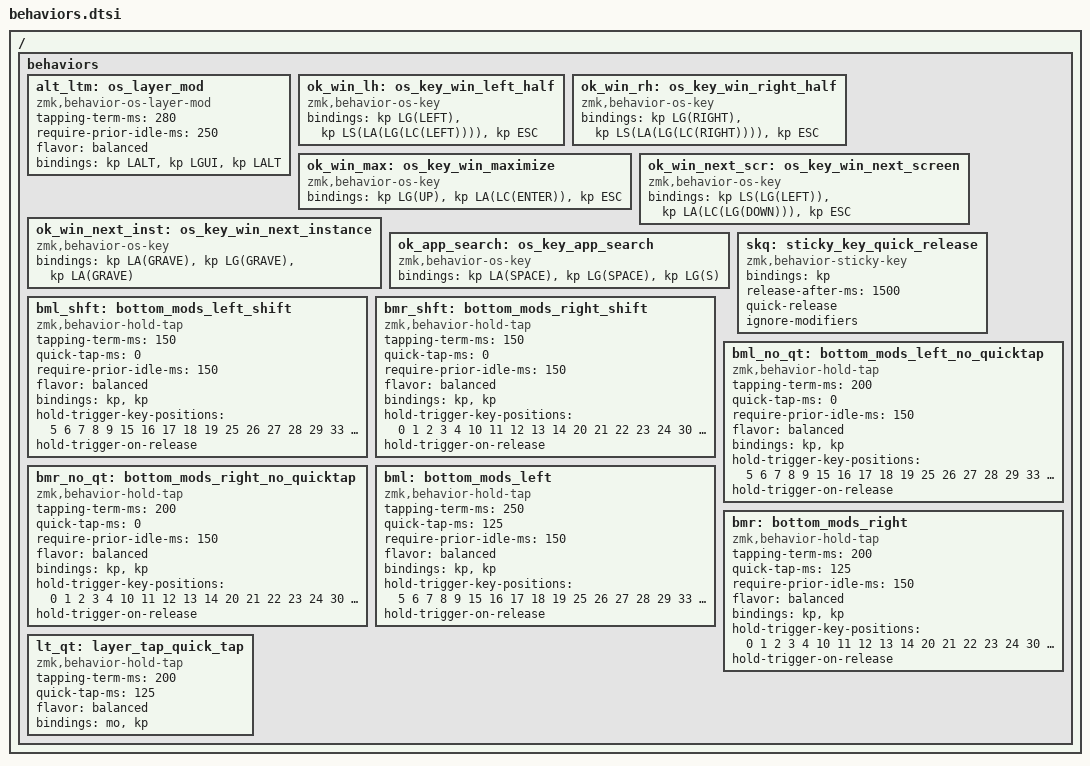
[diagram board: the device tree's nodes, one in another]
/ {
    behaviors {
        alt_ltm: os_layer_mod {
            compatible = "zmk,behavior-os-layer-mod";
            #binding-cells = <2>;
            tapping-term-ms = <280>;
            require-prior-idle-ms = <250>;
            flavor = "balanced";
            /*             Win         Mac         Lin  */
            bindings = <&kp LALT>, <&kp LGUI>, <&kp LALT>;
        };

        ok_win_lh: os_key_win_left_half {
            compatible = "zmk,behavior-os-key";
            #binding-cells = <0>;
            /*            Win           Mac           Lin  */
            bindings = <&kp LG(LEFT)>, <&kp LS(LA(LG(LC(LEFT))))>, <&kp ESC>;
        };

        ok_win_rh: os_key_win_right_half {
            compatible = "zmk,behavior-os-key";
            #binding-cells = <0>;
            /*            Win           Mac           Lin  */
            bindings = <&kp LG(RIGHT)>, <&kp LS(LA(LG(LC(RIGHT))))>, <&kp ESC>;
        };

        ok_win_max: os_key_win_maximize {
            compatible = "zmk,behavior-os-key";
            #binding-cells = <0>;
            /*            Win           Mac           Lin  */
            bindings = <&kp LG(UP)>, <&kp LA(LC(ENTER))>, <&kp ESC>;
        };

        ok_win_next_scr: os_key_win_next_screen {
            compatible = "zmk,behavior-os-key";
            #binding-cells = <0>;
            /*            Win           Mac           Lin  */
            bindings = <&kp LS(LG(LEFT))>, <&kp LA(LC(LG(DOWN)))>, <&kp ESC>;
        };

        ok_win_next_inst: os_key_win_next_instance {
            compatible = "zmk,behavior-os-key";
            #binding-cells = <0>;
            /*            Win           Mac           Lin  */
            bindings = <&kp LA(GRAVE)>, <&kp LG(GRAVE)>, <&kp LA(GRAVE)>;
        };

        ok_app_search: os_key_app_search {
            compatible = "zmk,behavior-os-key";
            #binding-cells = <0>;
            /*            Win           Mac           Lin  */
            bindings = <&kp LA(SPACE)>, <&kp LG(SPACE)>, <&kp LG(S)>;
        };

        // Custom sticky key with quick release
        skq: sticky_key_quick_release {
            compatible = "zmk,behavior-sticky-key";
            #binding-cells = <1>;
            bindings = <&kp>;
            release-after-ms = <1500>;
            quick-release;
            ignore-modifiers;
        };

        // Bottom row shift mods (no quick-tap + shorter tapping term)
        bml_shft: bottom_mods_left_shift {
            compatible = "zmk,behavior-hold-tap";
            #binding-cells = <2>;
            tapping-term-ms = <150>;
            quick-tap-ms = <0>;
            require-prior-idle-ms = <150>;
            flavor = "balanced";
            bindings = <&kp>, <&kp>;
            hold-trigger-key-positions = <5 6 7 8 9 15 16 17 18 19 25 26 27 28 29 33 34 35>;
            hold-trigger-on-release;
        };

        bmr_shft: bottom_mods_right_shift {
            compatible = "zmk,behavior-hold-tap";
            #binding-cells = <2>;
            tapping-term-ms = <150>;
            quick-tap-ms = <0>;
            require-prior-idle-ms = <150>;
            flavor = "balanced";
            bindings = <&kp>, <&kp>;
            hold-trigger-key-positions = <0 1 2 3 4 10 11 12 13 14 20 21 22 23 24 30 31 32>;
            hold-trigger-on-release;
        };

        // Bottom row mods without quick-tap
        bml_no_qt: bottom_mods_left_no_quicktap {
            compatible = "zmk,behavior-hold-tap";
            #binding-cells = <2>;
            tapping-term-ms = <200>;
            quick-tap-ms = <0>;
            require-prior-idle-ms = <150>;
            flavor = "balanced";
            bindings = <&kp>, <&kp>;
            hold-trigger-key-positions = <5 6 7 8 9 15 16 17 18 19 25 26 27 28 29 33 34 35>;
            hold-trigger-on-release;
        };

        bmr_no_qt: bottom_mods_right_no_quicktap {
            compatible = "zmk,behavior-hold-tap";
            #binding-cells = <2>;
            tapping-term-ms = <200>;
            quick-tap-ms = <0>;
            require-prior-idle-ms = <150>;
            flavor = "balanced";
            bindings = <&kp>, <&kp>;
            hold-trigger-key-positions = <0 1 2 3 4 10 11 12 13 14 20 21 22 23 24 30 31 32>;
            hold-trigger-on-release;
        };

        // Bottom row mods with quick-tap (for keys you might double-tap)
        bml: bottom_mods_left {
            compatible = "zmk,behavior-hold-tap";
            #binding-cells = <2>;
            tapping-term-ms = <250>;
            quick-tap-ms = <125>;
            require-prior-idle-ms = <150>;
            flavor = "balanced";
            bindings = <&kp>, <&kp>;
            hold-trigger-key-positions = <5 6 7 8 9 15 16 17 18 19 25 26 27 28 29 33 34 35>;
            hold-trigger-on-release;
        };

        bmr: bottom_mods_right {
            compatible = "zmk,behavior-hold-tap";
            #binding-cells = <2>;
            tapping-term-ms = <200>;
            quick-tap-ms = <125>;
            require-prior-idle-ms = <150>;
            flavor = "balanced";
            bindings = <&kp>, <&kp>;
            hold-trigger-key-positions = <0 1 2 3 4 10 11 12 13 14 20 21 22 23 24 30 31 32>;
            hold-trigger-on-release;
        };

        // Layer-tap with quick-tap for DEL and BSPC
        lt_qt: layer_tap_quick_tap {
            compatible = "zmk,behavior-hold-tap";
            #binding-cells = <2>;
            tapping-term-ms = <200>;
            quick-tap-ms = <125>;
            flavor = "balanced";
            bindings = <&mo>, <&kp>;
        };
    };
};
